# PIC32CK0512SG00100 device description
Architecture: CORTEX-M33; Family: PIC32CK; Series: PIC32CKSG00
Registers are 32-bit, read-write, reset 0x0 unless marked. A register's access mark holds for its fields unless they carry their own. Offsets are from the block's base; [hi:lo] are bit positions; {n}, {i} and the like mark numbered series; <NAME> marks a mode.

## FPB — Flash Patch and Breakpoint
Instances: FPB 0xE0002000
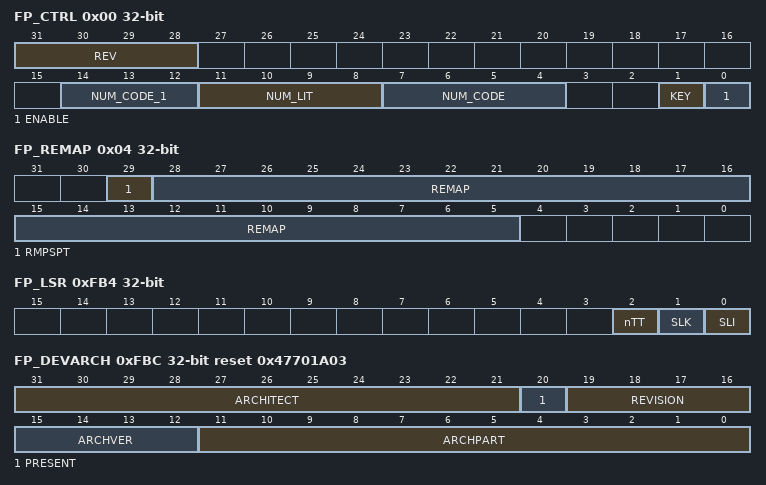
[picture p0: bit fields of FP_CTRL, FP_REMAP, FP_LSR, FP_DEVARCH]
0x00 FP_CTRL reset not defined — Flash Patch Control Register
  [31:28] REV — Revision
  [14:12] NUM_CODE_1 — Number of implemented code comparators bits [6:4]
  [11:8] NUM_LIT — Number of literal comparators
  [7:4] NUM_CODE — Number of implemented code comparators bits [3:0]
  [1] KEY — FP_CTRL write-enable key
  [0] ENABLE — Flash Patch global enable
0x04 FP_REMAP ro reset not defined — Flash Patch Remap Register
  [29] RMPSPT — Remap supported
  [28:5] REMAP — Remap address
{0x8+4i} FP_COMP[{i}] (i=0..7) reset not defined — Flash Patch Comparator Register n
  [0] BE — Breakpoint enable
  [31:1] BPADDR <BREAKPOINT> — Breakpoint address
  [31] FE <DEFAULT> — Flash Patch enable
  [28:2] FPADDR <DEFAULT> — Flash Patch address
0xFB0 FP_LAR wo reset not defined — FPB Software Lock Access Register
  [31:0] KEY — Lock access control
    0xC5ACCE55=UNLOCK (Unlock key value)
0xFB4 FP_LSR ro reset not defined — FPB Software Lock Status Register
  [2] nTT — Not thirty-two bit
  [1] SLK — Software Lock status
  [0] SLI — Software Lock implemented
0xFBC FP_DEVARCH ro reset 0x47701A03 — FPB Device Architecture Register
  [31:21] ARCHITECT
  [20] PRESENT — DEVARCH Present
  [19:16] REVISION
  [15:12] ARCHVER — Architecture Version
  [11:0] ARCHPART — Architecture Part
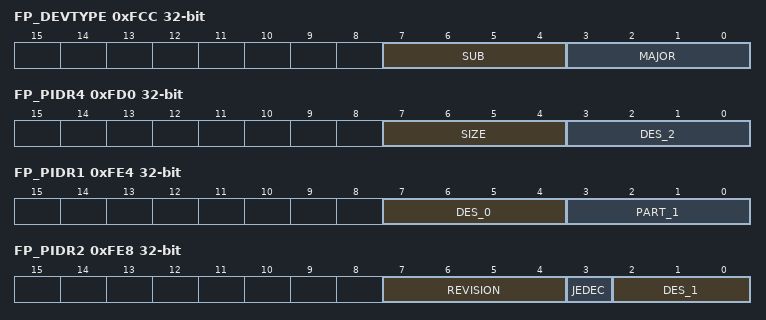
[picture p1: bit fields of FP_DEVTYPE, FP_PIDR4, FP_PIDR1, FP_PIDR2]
0xFCC FP_DEVTYPE ro — FPB Device Type Register
  [7:4] SUB — Sub-type
  [3:0] MAJOR — Major type
0xFD0 FP_PIDR4 ro reset not defined — FP Peripheral Identification Register 4
  [7:4] SIZE — 4KB count
  [3:0] DES_2 — JEP106 continuation code
{0xFC0+4i} FP_PIDR{i} ro (i=5..7) — FP Peripheral Identification Register {i}
0xFE0 FP_PIDR0 ro reset not defined — FP Peripheral Identification Register 0
  [7:0] PART_0 — Part number bits[7:0]
0xFE4 FP_PIDR1 ro reset not defined — FP Peripheral Identification Register 1
  [7:4] DES_0 — JEP106 identification code bits [3:0]
  [3:0] PART_1 — Part number bits[11:8]
0xFE8 FP_PIDR2 ro reset not defined — FP Peripheral Identification Register 2
  [7:4] REVISION — Component revision
  [3] JEDEC — JEDEC assignee value is used
  [2:0] DES_1 — JEP106 identification code bits[6:4]
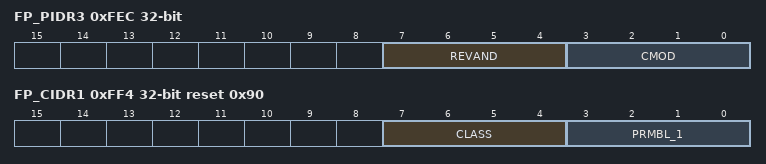
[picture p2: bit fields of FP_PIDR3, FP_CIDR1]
0xFEC FP_PIDR3 ro reset not defined — FP Peripheral Identification Register 3
  [7:4] REVAND
  [3:0] CMOD — Customer Modified
0xFF0 FP_CIDR0 ro reset 0xD — FP Component Identification Register 0
  [7:0] PRMBL_0 — CoreSight component identification preamble
0xFF4 FP_CIDR1 ro reset 0x90 — FP Component Identification Register 1
  [7:4] CLASS — CoreSight component class
  [3:0] PRMBL_1 — CoreSight component identification preamble
0xFF8 FP_CIDR2 ro reset 0x5 — FP Component Identification Register 2
  [7:0] PRMBL_2 — CoreSight component identification preamble
0xFFC FP_CIDR3 ro reset 0xB1 — FP Component Identification Register 3
  [7:0] PRMBL_3 — CoreSight component identification preamble

## FPU — Floating-point Extension
Instances: FPU 0xE000EF30, FPU_NS 0xE002EF30
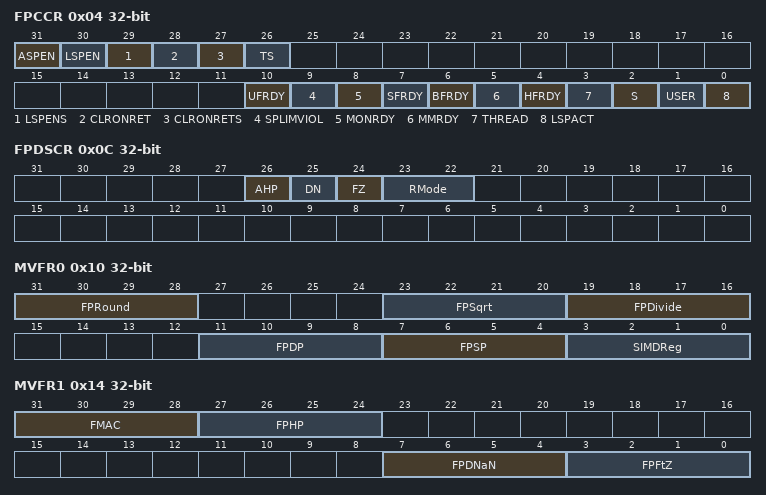
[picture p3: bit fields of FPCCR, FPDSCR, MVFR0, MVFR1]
0x04 FPCCR reset not defined — Floating-Point Context Control Register
  [31] ASPEN — Automatic FP context save enable
  [30] LSPEN — Automatic lazy FP context save enable
  [29] LSPENS — LSPEN field writeable only from Secure state
  [28] CLRONRET — Clear FP caller saved registers enable
  [27] CLRONRETS — CLRONRET field writeable only from Secure state
  [26] TS — Treat FP registers as Secure enable
  [10] UFRDY — UsageFault exception set to pending
  [9] SPLIMVIOL — FP context violates the stack pointer limit
  [8] MONRDY — DebugMonitor exception set to pending
  [7] SFRDY — SecureFault exception set to pending
  [6] BFRDY — BusFault exception set to pending
  [5] MMRDY — MemManage exception set to pending
  [4] HFRDY — HardFault exception set to pending
  [3] THREAD — Thread mode when FP stack frame allocated
  [2] S — Security status of FP context
  [1] USER — Privilege level when FP stack frame allocated
  [0] LSPACT — Lazy preservation of FP state active
0x08 FPCAR reset not defined — Floating-Point Context Address Register
  [31:3] ADDRESS — Address for FP registers push to exception stack
0x0C FPDSCR reset not defined — Floating-Point Default Status Control Register
  [26] AHP — Alternative half-precision default value
  [25] DN — NaN default value
  [24] FZ — Flush-to-zero default value
  [23:22] RMode — Rounding mode default value
0x10 MVFR0 ro reset not defined — Media and VFP Feature Register 0
  [31:28] FPRound — All FP rounding modes support
  [23:20] FPSqrt — FP square root operations support
  [19:16] FPDivide — FP divide operations support
  [11:8] FPDP — FP double-precision operations support
    2=YES (Supported)
  [7:4] FPSP — FP single-precision operations support
    2=YES (Supported)
  [3:0] SIMDReg — Size of FP register file
    1=16 x 64-bit registers
0x14 MVFR1 ro reset not defined — Media and VFP Feature Register 1
  [31:28] FMAC — Fused multiply accumulate instructions
  [27:24] FPHP — Floating-point half-precision conversion instructions
    1=SP (Half-precision to single-precision supported); 2=BOTH (Half-precision to single- and double-precision supported)
  [7:4] FPDNaN — Propagation of NaN values support
  [3:0] FPFtZ — Floating-point subnormals flush-to-zero
0x18 MVFR2 ro reset not defined — Media and VFP Feature Register 2
  [7:4] FPMisc — Floating-point miscellaneous features support
    4=YES (Selection, directed conversion to integer, VMINNM, and VMAXNM supported)

## Notices in the file
Copyright (c) 2021 Microchip Technology Inc.
SPDX-License-Identifier: Apache-2.0
Licensed under the Apache License, Version 2.0 (the "License");
you may not use this file except in compliance with the License.
You may obtain a copy of the License at
http://www.apache.org/licenses/LICENSE-2.0
Unless required by applicable law or agreed to in writing, software
distributed under the License is distributed on an "AS IS" BASIS,
WITHOUT WARRANTIES OR CONDITIONS OF ANY KIND, either express or implied.
See the License for the specific language governing permissions and
limitations under the License.
